# APM32F103xx register map
File version: 1.0
CPU: CM3 r2p1, little endian, no MPU, no FPU, 4 interrupt priority bits
Registers are 32-bit, read-write, reset 0x0 unless marked. A register's access mark holds for its fields unless they carry their own. Offsets are from the block's base; [hi:lo] are bit positions; {n}, {i} and the like mark numbered series.

## DAC — Digital to analog converter
Base 0x40007400
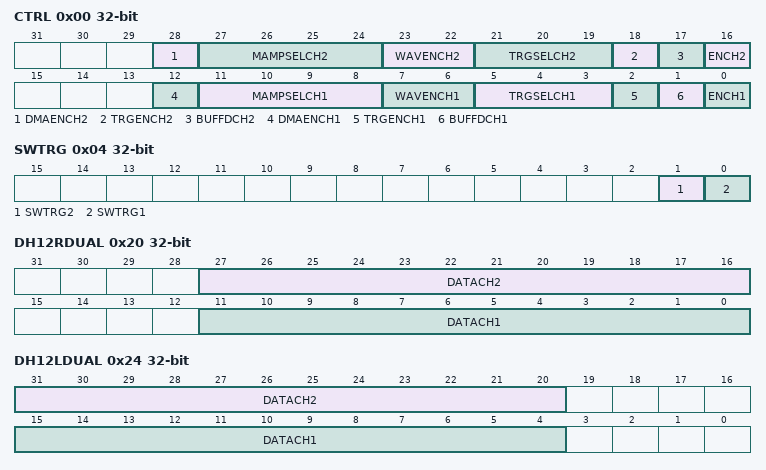
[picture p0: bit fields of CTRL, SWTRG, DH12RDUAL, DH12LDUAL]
0x00 CTRL — Control register (DAC_CTRL)
  [28] DMAENCH2 — DAC channel2 DMA enable
  [27:24] MAMPSELCH2 — DAC channel2 mask/amplitude selector
  [23:22] WAVENCH2 — DAC channel2 noise/triangle wave generation enable
  [21:19] TRGSELCH2 — DAC channel2 trigger selection
  [18] TRGENCH2 — DAC channel2 trigger enable
  [17] BUFFDCH2 — DAC channel2 output buffer disable
  [16] ENCH2 — DAC channel2 enable
  [12] DMAENCH1 — DAC channel1 DMA enable
  [11:8] MAMPSELCH1 — DAC channel1 mask/amplitude selector
  [7:6] WAVENCH1 — DAC channel1 noise/triangle wave generation enable
  [5:3] TRGSELCH1 — DAC channel1 trigger selection
  [2] TRGENCH1 — DAC channel1 trigger enable
  [1] BUFFDCH1 — DAC channel1 output buffer disable
  [0] ENCH1 — DAC channel1 enable
0x04 SWTRG wo — DAC software trigger register (DAC_SWTRG)
  [1] SWTRG2 — DAC channel2 software trigger
  [0] SWTRG1 — DAC channel1 software trigger
0x08 DH12R1 — DAC channel1 12-bit right-aligned data holding register(DAC_DH12R1)
  [11:0] DATA — DAC channel1 12-bit right-aligned data
0x0C DH12L1 — DAC channel1 12-bit left aligned data holding register (DAC_DH12L1)
  [15:4] DATA — DAC channel1 12-bit left-aligned data
0x10 DH8R1 — DAC channel1 8-bit right aligned data holding register (DAC_DH8R1)
  [7:0] DATA — DAC channel1 8-bit right-aligned data
0x14 DH12R2 — DAC channel1 12-bit right-aligned data holding register(DAC_DH12R2)
  [11:0] DATA — DAC channel2 12-bit right-aligned data
0x18 DH12L2 — DAC channel1 12-bit left aligned data holding register (DAC_DH12L2)
  [15:4] DATA — DAC channel2 12-bit left-aligned data
0x1C DH8R2 — DAC channel1 8-bit right aligned data holding register (DAC_DH8R1)
  [7:0] DATA — DAC channel2 8-bit right-aligned data
0x20 DH12RDUAL — Dual DAC 12-bit right-aligned data holding register (DAC_DH12RDUAL), Bits 31:28 Reserved, Bits 15:12 Reserved
  [27:16] DATACH2 — DAC channel2 12-bit right-aligned data
  [11:0] DATACH1 — DAC channel1 12-bit right-aligned data
0x24 DH12LDUAL — DUAL DAC 12-bit left aligned data holding register (DAC_DH12LDUAL), Bits 19:16 Reserved, Bits 3:0 Reserved
  [31:20] DATACH2 — DAC channel2 12-bit right-aligned data
  [15:4] DATACH1 — DAC channel1 12-bit left-aligned data
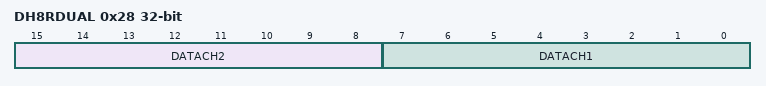
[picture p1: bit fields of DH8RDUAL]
0x28 DH8RDUAL — DUAL DAC 8-bit right aligned data holding register (DAC_DH8RDUAL), Bits 31:16 Reserved
  [15:8] DATACH2 — DAC channel2 8-bit right-aligned data
  [7:0] DATACH1 — DAC channel1 8-bit right-aligned data
0x2C DATAOCH1 ro — DAC channel1 data output register (DAC_DATAOCH1)
  [11:0] DATA — DAC channel1 data output
0x30 DATAOCH2 ro — DAC channel2 data output register (DAC_DATAOCH2)
  [11:0] DATA — DAC channel2 data output

## DBGMCU — Debug support
Base 0xE0042000
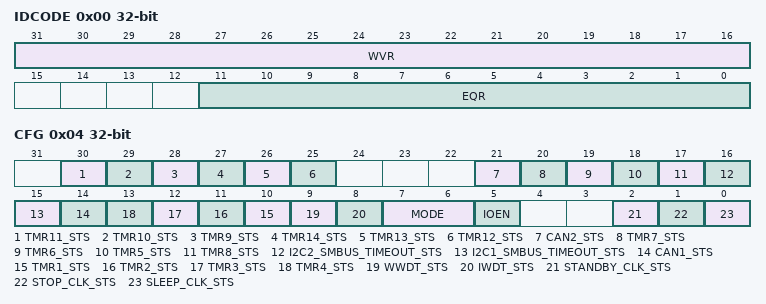
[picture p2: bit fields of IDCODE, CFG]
0x00 IDCODE ro — DBGMCU_IDCODE
  [31:16] WVR — Wafer Version Recognition
  [11:0] EQR — Equipment Recognition
0x04 CFG — DBGMCU_CFG
  [30] TMR11_STS, [29] TMR10_STS, [28] TMR9_STS, [27] TMR14_STS, [26] TMR13_STS, [25] TMR12_STS, [21] CAN2_STS, [20] TMR7_STS, [19] TMR6_STS, [18] TMR5_STS, [17] TMR8_STS, [16] I2C2_SMBUS_TIMEOUT_STS, [15] I2C1_SMBUS_TIMEOUT_STS, [14] CAN1_STS, [n+9] TMR{n}_STS (n=1..4), [9] WWDT_STS, [8] IWDT_STS, [7:6] MODE, [5] IOEN, [2] STANDBY_CLK_STS, [1] STOP_CLK_STS, [0] SLEEP_CLK_STS

## SDIO — Secure digital input/output interface
Base 0x40018000
0x00 PWRCTRL — Bits 1:0 = PWRCTRL: Power supply control bits
  [1:0] PWRCTRL
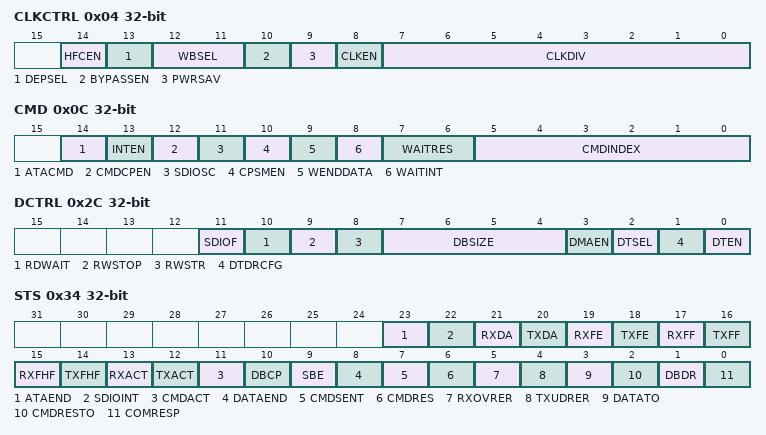
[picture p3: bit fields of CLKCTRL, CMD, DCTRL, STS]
0x04 CLKCTRL — SDI clock control register (SDIO_CLKCR)
  [14] HFCEN — HW Flow Control enable
  [13] DEPSEL — SDIO_CK dephasing selection bit
  [12:11] WBSEL — Wide bus mode enable bit
  [10] BYPASSEN — Clock divider bypass enable bit
  [9] PWRSAV — Power saving configuration bit
  [8] CLKEN — Clock enable bit
  [7:0] CLKDIV — Clock divide factor
0x08 ARG — Bits 31:0 = : Command argument
  [31:0] CMDARG — Command argument
0x0C CMD — SDIO command register (SDIO_CMD)
  [14] ATACMD, [13] INTEN, [12] CMDCPEN, [11] SDIOSC, [10] CPSMEN, [9] WENDDATA, [8] WAITINT, [7:6] WAITRES, [5:0] CMDINDEX
0x10 CMDRES ro — SDIO command register
  [5:0] CMDRES
{0x10+4i} RES{i} ro (i=1..4) — Bits 31:0 = CARDSTATUS{i}
  [31:0] CARDSTS{i}
0x24 DATATIME — Bits 31:0 = DATATIME: Data timeout period
  [31:0] DATATIME — Data timeout period
0x28 DATALEN — Bits 24:0 = DATALENGTH: Data length value
  [24:0] DATALEN — Data length value
0x2C DCTRL — SDIO data control register (SDIO_DCTRL)
  [11] SDIOF, [10] RDWAIT, [9] RWSTOP, [8] RWSTR, [7:4] DBSIZE, [3] DMAEN, [2] DTSEL, [1] DTDRCFG, [0] DTEN
0x30 DCNT ro — Bits 24:0 = DATACOUNT: Data count value
  [24:0] DATACNT — Data count value
0x34 STS ro — SDIO status register (SDIO_STS)
  [23] ATAEND, [22] SDIOINT, [21] RXDA, [20] TXDA, [19] RXFE, [18] TXFE, [17] RXFF, [16] TXFF, [15] RXFHF, [14] TXFHF, [13] RXACT, [12] TXACT, [11] CMDACT, [10] DBCP, [9] SBE, [8] DATAEND, [7] CMDSENT, [6] CMDRES, [5] RXOVRER, [4] TXUDRER, [3] DATATO, [2] CMDRESTO, [1] DBDR, [0] COMRESP
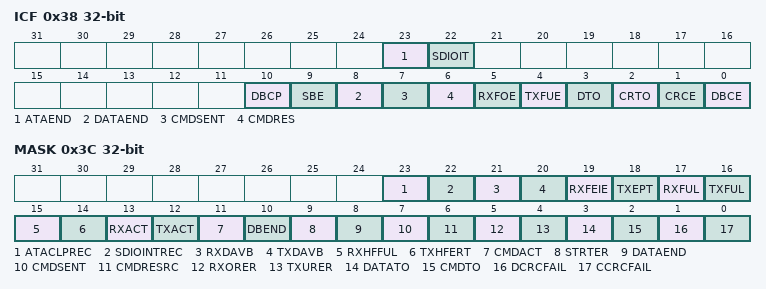
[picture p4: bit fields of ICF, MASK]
0x38 ICF — SDIO interrupt clear register (SDIO_ICF)
  [23] ATAEND, [22] SDIOIT, [10] DBCP, [9] SBE, [8] DATAEND, [7] CMDSENT, [6] CMDRES, [5] RXFOE, [4] TXFUE, [3] DTO, [2] CRTO, [1] CRCE, [0] DBCE
0x3C MASK — SDIO mask register (SDIO_MASK)
  [23] ATACLPREC
  [22] SDIOINTREC
  [21] RXDAVB
  [20] TXDAVB
  [19] RXFEIE
  [18] TXEPT
  [17] RXFUL
  [16] TXFUL
  [15] RXHFFUL
  [14] TXHFERT — TXFERT
  [13] RXACT
  [12] TXACT
  [11] CMDACT
  [10] DBEND
  [9] STRTER
  [8] DATAEND
  [7] CMDSENT
  [6] CMDRESRC
  [5] RXORER
  [4] TXURER
  [3] DATATO
  [2] CMDTO
  [1] DCRCFAIL
  [0] CCRCFAIL
0x48 FIFOCNT ro — Bits 23:0 = FIFOCOUNT: Remaining number of words to be written to or read from the FIFO
  [23:0] FIFOCNT
0x80 FIFODATA — bits 31:0 = FIFOData: Receive and transmit FIFO data
